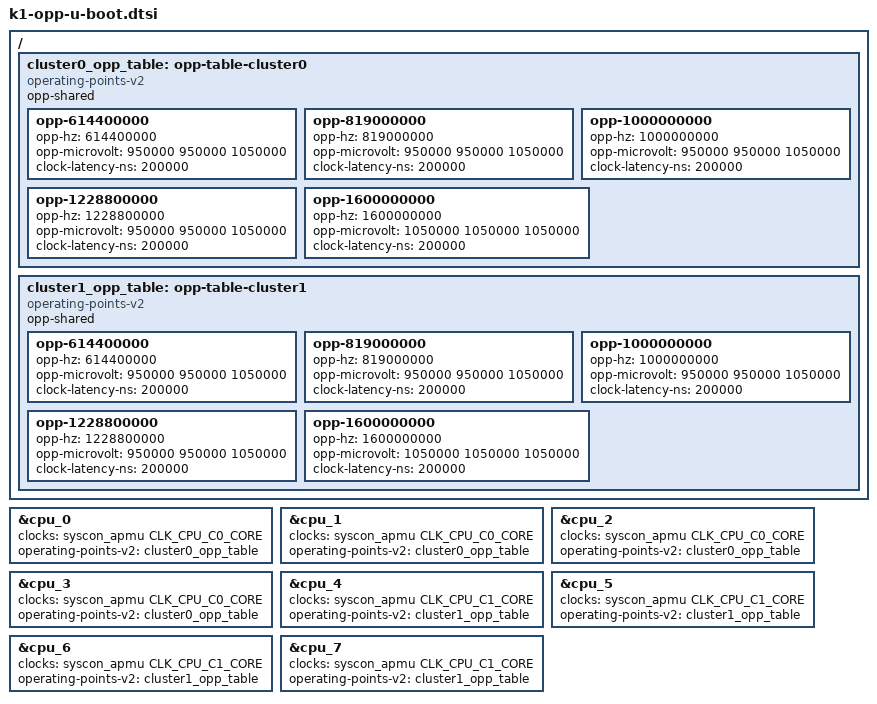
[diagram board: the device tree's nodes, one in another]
// SPDX-License-Identifier: GPL-2.0-or-later OR MIT
/*
 * CPU cluster clocks and operating points of the SpacemiT K1, as Linux
 * describes them after v7.2: the "clocks" of each CPU node from k1.dtsi and
 * the two cluster tables of k1-opp.dtsi. dts/upstream (v7.2) has neither yet;
 * remove this file once it does.
 */

/ {
	cluster0_opp_table: opp-table-cluster0 {
		compatible = "operating-points-v2";
		opp-shared;

		opp-614400000 {
			opp-hz = /bits/ 64 <614400000>;
			opp-microvolt = <950000 950000 1050000>;
			clock-latency-ns = <200000>;
		};

		opp-819000000 {
			opp-hz = /bits/ 64 <819000000>;
			opp-microvolt = <950000 950000 1050000>;
			clock-latency-ns = <200000>;
		};

		opp-1000000000 {
			opp-hz = /bits/ 64 <1000000000>;
			opp-microvolt = <950000 950000 1050000>;
			clock-latency-ns = <200000>;
		};

		opp-1228800000 {
			opp-hz = /bits/ 64 <1228800000>;
			opp-microvolt = <950000 950000 1050000>;
			clock-latency-ns = <200000>;
		};

		opp-1600000000 {
			opp-hz = /bits/ 64 <1600000000>;
			opp-microvolt = <1050000 1050000 1050000>;
			clock-latency-ns = <200000>;
		};
	};

	cluster1_opp_table: opp-table-cluster1 {
		compatible = "operating-points-v2";
		opp-shared;

		opp-614400000 {
			opp-hz = /bits/ 64 <614400000>;
			opp-microvolt = <950000 950000 1050000>;
			clock-latency-ns = <200000>;
		};

		opp-819000000 {
			opp-hz = /bits/ 64 <819000000>;
			opp-microvolt = <950000 950000 1050000>;
			clock-latency-ns = <200000>;
		};

		opp-1000000000 {
			opp-hz = /bits/ 64 <1000000000>;
			opp-microvolt = <950000 950000 1050000>;
			clock-latency-ns = <200000>;
		};

		opp-1228800000 {
			opp-hz = /bits/ 64 <1228800000>;
			opp-microvolt = <950000 950000 1050000>;
			clock-latency-ns = <200000>;
		};

		opp-1600000000 {
			opp-hz = /bits/ 64 <1600000000>;
			opp-microvolt = <1050000 1050000 1050000>;
			clock-latency-ns = <200000>;
		};
	};
};

&cpu_0 {
	clocks = <&syscon_apmu CLK_CPU_C0_CORE>;
	operating-points-v2 = <&cluster0_opp_table>;
};

&cpu_1 {
	clocks = <&syscon_apmu CLK_CPU_C0_CORE>;
	operating-points-v2 = <&cluster0_opp_table>;
};

&cpu_2 {
	clocks = <&syscon_apmu CLK_CPU_C0_CORE>;
	operating-points-v2 = <&cluster0_opp_table>;
};

&cpu_3 {
	clocks = <&syscon_apmu CLK_CPU_C0_CORE>;
	operating-points-v2 = <&cluster0_opp_table>;
};

&cpu_4 {
	clocks = <&syscon_apmu CLK_CPU_C1_CORE>;
	operating-points-v2 = <&cluster1_opp_table>;
};

&cpu_5 {
	clocks = <&syscon_apmu CLK_CPU_C1_CORE>;
	operating-points-v2 = <&cluster1_opp_table>;
};

&cpu_6 {
	clocks = <&syscon_apmu CLK_CPU_C1_CORE>;
	operating-points-v2 = <&cluster1_opp_table>;
};

&cpu_7 {
	clocks = <&syscon_apmu CLK_CPU_C1_CORE>;
	operating-points-v2 = <&cluster1_opp_table>;
};
